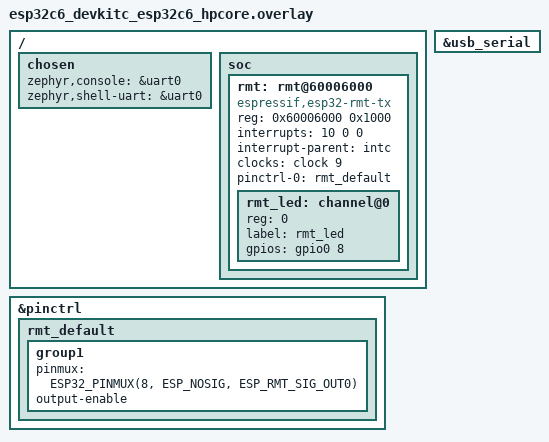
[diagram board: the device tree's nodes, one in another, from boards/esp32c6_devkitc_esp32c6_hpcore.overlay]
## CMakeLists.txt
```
# CMakeLists.txt for Zephyr LED Application
# Updated to support both ESP32 C6 and S3 DevKit boards

cmake_minimum_required(VERSION 3.20.0)
find_package(Zephyr REQUIRED HINTS $ENV{ZEPHYR_BASE})
project(zephyr_led_app)

# Add source files
target_sources(app PRIVATE src/main.c)

# Add custom drivers and includes
zephyr_include_directories(include)
add_subdirectory(drivers)
```

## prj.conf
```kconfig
# Zephyr configuration for LED Application
# This configuration supports both ESP32 C6 and S3 DevKit boards

# Enable logging
CONFIG_LOG=y
# Use Immediate mode to see logs as they happen
CONFIG_LOG_MODE_IMMEDIATE=y
CONFIG_LOG_BACKEND_UART=y
CONFIG_LOG_DEFAULT_LEVEL=3
CONFIG_LOG_PRINTK=y

# Enable Console
CONFIG_CONSOLE=y
CONFIG_UART_CONSOLE=y
CONFIG_PRINTK=y
CONFIG_BOOT_BANNER=y

# Give the USB host time to connect (not needed for UART but safe)
CONFIG_BOOT_DELAY=1500

# Enable standard ESP32 UART
CONFIG_SERIAL=y
CONFIG_UART_ESP32=y

# Support for ESP32/C6/S3 Built-in USB-Serial/JTAG controller (can stay enabled)
CONFIG_SERIAL_ESP32_USB=y

# Enable GPIO driver
CONFIG_GPIO=y

# Enable custom RMT TX driver
CONFIG_RMT_TX=y
CONFIG_RMT_TX_ESP32=y
CONFIG_RMT_TX_LOG_LEVEL_DBG=y

# Initialization priorities: Parent MUST be lower than Child
CONFIG_RMT_TX_INIT_PRIORITY=80
CONFIG_RMT_TX_CHANNEL_INIT_PRIORITY=90

# Increase main stack size for safety
CONFIG_MAIN_STACK_SIZE=4096
```

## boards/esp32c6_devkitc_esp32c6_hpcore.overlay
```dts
#include <zephyr/dt-bindings/pinctrl/esp-pinctrl-common.h>
#include <zephyr/dt-bindings/pinctrl/esp32c6-pinctrl.h>
#include <zephyr/dt-bindings/pinctrl/esp32c6-gpio-sigmap.h>

/ {
    chosen {
        zephyr,console = &uart0;
        zephyr,shell-uart = &uart0;
    };

    soc {
        rmt: rmt@60006000 {
            compatible = "espressif,esp32-rmt-tx";
            reg = <0x60006000 0x1000>;
            interrupts = <10 0 0>;
            interrupt-parent = <&intc>;
            clocks = <&clock 9>;
            #address-cells = <1>;
            #size-cells = <0>;
            status = "okay";
            pinctrl-0 = <&rmt_default>;
            pinctrl-names = "default";

            rmt_led: channel@0 {
                reg = <0>;
                label = "rmt_led";
                gpios = <&gpio0 8 GPIO_ACTIVE_HIGH>;
            };
        };
    };
};

&pinctrl {
    rmt_default: rmt_default {
        group1 {
            pinmux = <ESP32_PINMUX(8, ESP_NOSIG, ESP_RMT_SIG_OUT0)>;
            output-enable;
        };
    };
};

&usb_serial {
    status = "okay";
};
```

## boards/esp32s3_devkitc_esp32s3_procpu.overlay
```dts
#include <zephyr/dt-bindings/pinctrl/esp-pinctrl-common.h>
#include <zephyr/dt-bindings/pinctrl/esp32s3-pinctrl.h>
#include <zephyr/dt-bindings/pinctrl/esp32s3-gpio-sigmap.h>

/ {
    chosen {
        zephyr,console = &uart0;
        zephyr,shell-uart = &uart0;
    };

    soc {
        rmt: rmt@60016000 {
            compatible = "espressif,esp32-rmt-tx";
            reg = <0x60016000 0x1000>;
            interrupts = <45 0 0>;
            interrupt-parent = <&intc>;
            clocks = <&clock 18>;
            #address-cells = <1>;
            #size-cells = <0>;
            status = "okay";
            pinctrl-0 = <&rmt_default>;
            pinctrl-names = "default";

            rmt_led: channel@0 {
                reg = <0>;
                label = "rmt_led";
                // Pick a default GPIO, it doesn't matter because the main program will scan them all.
                gpios = <&gpio1 16 GPIO_ACTIVE_HIGH>;
            };
        };
    };
};

&pinctrl {
    rmt_default: rmt_default {
        group1 {
            pinmux = <ESP32_PINMUX(48, ESP_NOSIG, ESP_RMT_SIG_OUT0)>;
            output-enable;
        };
    };
};

&usb_serial {
    status = "okay";
};
```

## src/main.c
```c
#include <zephyr/kernel.h>
#include <zephyr/drivers/gpio.h>
#include <zephyr/logging/log.h>
#include <zephyr/devicetree.h>
#include <zephyr/drivers/rmt_tx.h>
#include <stdio.h>
#include <esp_rom_gpio.h>
#include <soc/gpio_sig_map.h>

LOG_MODULE_REGISTER(app, CONFIG_LOG_DEFAULT_LEVEL);

/* Get the RMT channel node from alias or specific label */
#define RMT_LED_NODE DT_NODELABEL(rmt_led)

/* WS2812 timings assuming an 80MHz RMT clock (12.5ns per tick) */
#define T0H 32  // 400ns
#define T0L 68  // 850ns
#define T1H 64  // 800ns
#define T1L 36  // 450ns

void set_ws2812_color(struct rmt_symbol *symbols, uint8_t r, uint8_t g, uint8_t b) {
    // WS2812 expects GRB order
    uint32_t color = (g << 16) | (r << 8) | b;
    for (int i = 0; i < 24; i++) {
        int bit = (color >> (23 - i)) & 1;
        symbols[i].level0 = 1;
        symbols[i].level1 = 0;
        if (bit) {
            symbols[i].duration0 = T1H;
            symbols[i].duration1 = T1L;
        } else {
            symbols[i].duration0 = T0H;
            symbols[i].duration1 = T0L;
        }
    }
}

int main(void)
{
    // Wait for the USB console to stabilize
    k_sleep(K_MSEC(500));
    printk("\n\n*** APPLICATION START ***\n\n");
    LOG_INF("Starting Zephyr LED Blinker");

    const struct device *rmt_dev = NULL;

#if DT_NODE_HAS_STATUS(RMT_LED_NODE, okay)
    rmt_dev = DEVICE_DT_GET(RMT_LED_NODE);
#endif

    if (!device_is_ready(rmt_dev)) {
        LOG_ERR("RMT Device not ready");
        return -1;
    }

    struct rmt_symbol symbols[24];

    // The dynamic signal routing and GPIO scanning logic has been removed as per the request to blink a single LED.
    // It is assumed that the RMT_LED_NODE is properly configured in the device tree to control the target LED.

    while (1) {
        // Assuming max color value is 100 based on previous code. 50% power is 50.
        // Blink Red (1s period, 50% power)
				LOG_INF("LED blink sequence - RED");
        set_ws2812_color(symbols, 50, 0, 0);
        rmt_tx_transmit(rmt_dev, symbols, 24, K_MSEC(500));
        k_sleep(K_MSEC(500)); // LED ON for 1s
        set_ws2812_color(symbols, 0, 0, 0); // Turn off
        rmt_tx_transmit(rmt_dev, symbols, 24, K_MSEC(500));
        k_sleep(K_MSEC(500)); // LED OFF for 1s

        // Blink Green (1s period, 50% power)
				LOG_INF("LED blink sequence - GREEN");
        set_ws2812_color(symbols, 0, 50, 0);
        rmt_tx_transmit(rmt_dev, symbols, 24, K_MSEC(500));
        k_sleep(K_MSEC(500));
        set_ws2812_color(symbols, 0, 0, 0); // Turn off
        rmt_tx_transmit(rmt_dev, symbols, 24, K_MSEC(500));
        k_sleep(K_MSEC(500));

        // Blink Blue (1s period, 50% power)
				LOG_INF("LED blink sequence - BLUE");
        set_ws2812_color(symbols, 0, 0, 50);
        rmt_tx_transmit(rmt_dev, symbols, 24, K_MSEC(500));
        k_sleep(K_MSEC(500));
        set_ws2812_color(symbols, 0, 0, 0); // Turn off
        rmt_tx_transmit(rmt_dev, symbols, 24, K_MSEC(500));
        k_sleep(K_MSEC(500));
    }

    return 0;
}
```
